AUTOSAR XML (schema 4-3-0)
standard types defined: uint8, uint8_DataConstr
package /ComponentTypes/HkmcDtcSWC
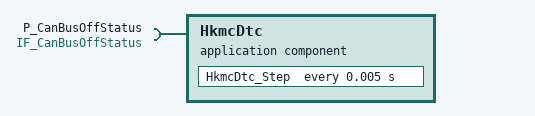
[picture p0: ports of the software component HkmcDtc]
  application sw component type HkmcDtc
    require port P_CanBusOffStatus: nonqueued-receiver-com-spec{data-element=DE_CanBusOffSatus, filter=data-filter-type=ALWAYS, init-value=0}, required-interface=IF_CanBusOffStatus
    behavior HkmcDtc_InternalBehavior
      timing event HkmcDtc_Step_TE: start-on-event=HkmcDtc_Step, period=0.005
      runnable HkmcDtc_Step
  swc implementation HkmcDtc_Implementation: behavior=HkmcDtc_InternalBehavior
    code-descriptors:
      code Default: artifact-descriptors=autosar-engineering-object={short-label=Default, category=SWSRC}
package /ComponentTypes/HkmcDtcSWC/PortInterfaces
  sender receiver interface IF_CanBusOffStatus: invalidation-policy{data-element=DE_CanBusOffSatus, handle-invalid=DONT-INVALIDATE}
    data DE_CanBusOffSatus: type=uint8
